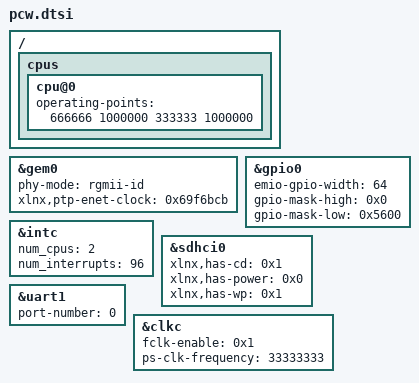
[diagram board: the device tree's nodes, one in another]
/*
 * CAUTION: This file is automatically generated by Xilinx.
 * Version:  
 * Today is: Wed Jan 31 18:22:32 2018
 */


/ {
	cpus {
		cpu@0 {
			operating-points = <666666 1000000 333333 1000000>;
		};
	};
};
&gem0 {
	phy-mode = "rgmii-id";
	status = "okay";
	xlnx,ptp-enet-clock = <0x69f6bcb>;
};
&gpio0 {
	emio-gpio-width = <64>;
	gpio-mask-high = <0x0>;
	gpio-mask-low = <0x5600>;
};
&intc {
	num_cpus = <2>;
	num_interrupts = <96>;
};
&sdhci0 {
	status = "okay";
	xlnx,has-cd = <0x1>;
	xlnx,has-power = <0x0>;
	xlnx,has-wp = <0x1>;
};
&uart1 {
	device_type = "serial";
	port-number = <0>;
	status = "okay";
};
&clkc {
	fclk-enable = <0x1>;
	ps-clk-frequency = <33333333>;
};
